# PY32F031xx register map
Vendor: Puya; Series: PY32F0; File version: 1.0.0
CPU: CM0+ r0p1, little endian, no MPU, no FPU, 4 interrupt priority bits
Registers are 32-bit, read-write, reset 0x0 unless marked. A register's access mark holds for its fields unless they carry their own. Offsets are from the block's base; [hi:lo] are bit positions; {n}, {i} and the like mark numbered series.

## SYSCFG — System configuration controller
Base 0x40010000
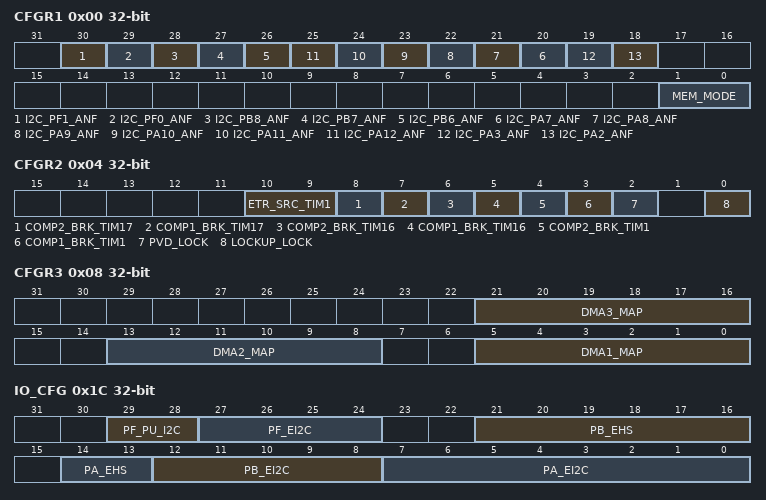
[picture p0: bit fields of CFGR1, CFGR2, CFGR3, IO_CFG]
0x00 CFGR1 — SYSCFG configuration register 1
  [30] I2C_PF1_ANF — Analog filter enable control driving capability activation bits PF1
  [29] I2C_PF0_ANF — Analog filter enable control driving capability activation bits PF0
  [28] I2C_PB8_ANF — Analog filter enable control driving capability activation bits PB8
  [27] I2C_PB7_ANF — Analog filter enable control driving capability activation bits PB7
  [26] I2C_PB6_ANF — Analog filter enable control driving capability activation bits PB6
  [n+13] I2C_PA{n}_ANF (n=7..12) — Analog filter enable control driving capability activation bits PA{n}
  [19] I2C_PA3_ANF — Analog filter enable control driving capability activation bits PA3
  [18] I2C_PA2_ANF — Analog filter enable control driving capability activation bits PA2
  [1:0] MEM_MODE — Memory mapping selection bits
0x04 CFGR2 — SYSCFG configuration register 2
  [10:9] ETR_SRC_TIM1 — TIM1 ETR source selection
  [8] COMP2_BRK_TIM17 — COMP2 is enable to input of TIM17 break
  [7] COMP1_BRK_TIM17 — COMP1 is enable to input of TIM17 break
  [6] COMP2_BRK_TIM16 — COMP2 is enable to input of TIM16 break
  [5] COMP1_BRK_TIM16 — COMP1 is enable to input of TIM16 break
  [4] COMP2_BRK_TIM1 — COMP2 is enable to input of TIM1 break
  [3] COMP1_BRK_TIM1 — COMP1 is enable to input of TIM1 break
  [2] PVD_LOCK — PVD lock enable bit
  [0] LOCKUP_LOCK — Cortex-M0+ LOCKUP bit enable bit
0x08 CFGR3 — SYSCFG configuration register 3
  [21:16] DMA3_MAP — DMA channel3 requeset selection
  [13:8] DMA2_MAP — DMA channel2 requeset selection
  [5:0] DMA1_MAP — DMA channel1 requeset selection
0x10 PA_ENS — GPIOA noise filter enable register
  [15:0] PA_ENS — Noise filter enable, active high
0x14 PB_ENS — GPIOB noise filter enable register
  [15:0] PB_ENS — Noise filter enable, active high
0x18 PF_ENS — GPIOF noise filter enable register
  [15:0] PF_ENS — Noise filter enable, active high
0x1C IO_CFG — I2C type IO configure register
  [29:28] PF_PU_I2C, [27:24] PF_EI2C, [21:16] PB_EHS, [14:13] PA_EHS, [12:8] PB_EI2C, [7:0] PA_EI2C
0x20 PA_ANA2EN — GPIOA Analog2 enable register
  [15:0] PA_ANA2EN — IO PORTA PAD_ANA2 enable
0x24 PB_ANA2EN — GPIOB Analog2 enable register
  [15:0] PB_ANA2EN — IO PORTB PAD_ANA2 enable
0x28 PF_ANA2EN — GPIOF Analog2 enable register
  [15:0] PF_ANA2EN — IO PORTF PAD_ANA2 enable

## DIV — Divider
Base 0x40023800
0x00 DEND — Dividend
0x04 SOR — Divisor
0x08 QUOT ro — Quotient
0x0C REMD ro — Remainder
0x10 SIGN — des SIGN
  [0] SIGN
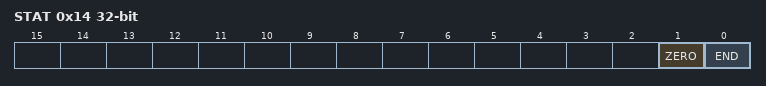
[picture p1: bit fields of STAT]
0x14 STAT — des SIGN
  [1] ZERO — des ZERO
  [0] END — des END

## CORDIC — Digital Co-process Operation
Base 0x40023400
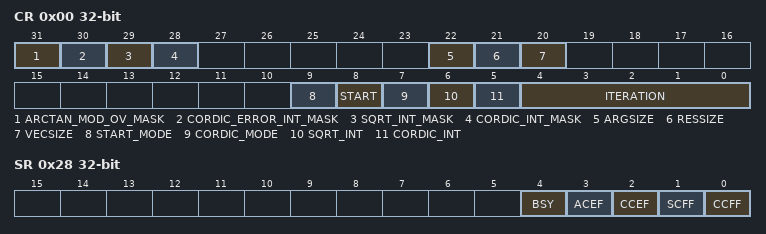
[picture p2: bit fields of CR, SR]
0x00 CR — CORDIC control register
  [31] ARCTAN_MOD_OV_MASK, [30] CORDIC_ERROR_INT_MASK, [29] SQRT_INT_MASK, [28] CORDIC_INT_MASK, [22] ARGSIZE, [21] RESSIZE, [20] VECSIZE, [9] START_MODE, [8] START, [7] CORDIC_MODE, [6] SQRT_INT, [5] CORDIC_INT, [4:0] ITERATION
0x04 THETA — SIN or COS input theta register
0x08 SIN ro — CORDIC SIN result register
  [23:0] SIN — SIN result
0x0C COS ro — CORDIC COS result register
  [23:0] COS — COS result
0x10 X — Arctan input coordinate register
  [23:0] X — arctan or module X register
0x14 Y — Arctan input coordinate register
  [23:0] Y — arctan or module Y register
0x18 MOD ro — CORDIC Mod result register
  [24:0] MOD — mod result
0x1C ARCTAN ro — CORDIC ARCTAN result register
  [15:0] ARCTAN — arctan result
0x20 DSP_RAD — CORDIC Radicand register
  [31:0] RAD — Number of open parties
0x24 DSP_SQRT ro — CORDIC SQRT result register
  [15:0] SQRT — sqrt result
0x28 SR ro — CORDIC Status register
  [4] BSY
  [3] ACEF — desc ACFF
  [2] CCEF — desc CCFF
  [1] SCFF
  [0] CCFF
